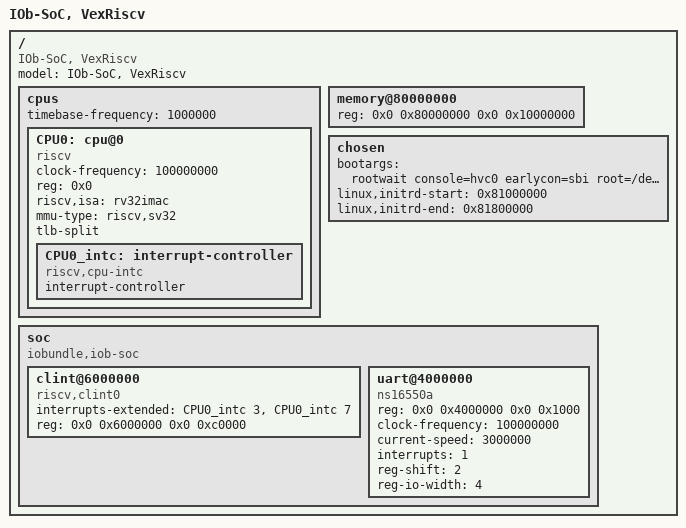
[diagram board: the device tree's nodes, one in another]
/dts-v1/;

/ {
  #address-cells = <2>;
  #size-cells = <2>;
  model = "IOb-SoC, VexRiscv";
  compatible = "IOb-SoC, VexRiscv";
	cpus {
    #address-cells = <0x1>;
    #size-cells = <0x0>;
    timebase-frequency = <1000000>;
		CPU0: cpu@0 {
			clock-frequency = <100000000>;
      device_type = "cpu";
			reg = <0x0>;
			status = "okay";
      compatible = "riscv";
			riscv,isa = "rv32imac";
			mmu-type = "riscv,sv32";
			tlb-split;
			CPU0_intc: interrupt-controller {
				#interrupt-cells = <1>;
				interrupt-controller;
				compatible = "riscv,cpu-intc";
			};
		};
	};
	memory@80000000 {
    device_type = "memory";
    reg = <0x0 0x80000000 0x0 0x10000000>;
	};
  chosen {
  	bootargs = "rootwait console=hvc0 earlycon=sbi root=/dev/ram0 init=/sbin/init";
  	linux,initrd-start = <0x81000000>;
  	linux,initrd-end = <0x81800000>; // max 8MB ramdisk image
  };
  soc {
    #address-cells = <2>;
    #size-cells = <2>;
    compatible = "iobundle,iob-soc", "simple-bus";
    ranges;
    clint@6000000 {
      compatible = "riscv,clint0";
      interrupts-extended = <&CPU0_intc 3 &CPU0_intc 7>;
      reg = <0x0 0x6000000 0x0 0xc0000>;
      reg-names = "control";
    };
    uart@4000000 {
      compatible = "ns16550a";
      reg = <0x0 0x4000000 0x0 0x1000>;
      clock-frequency = <100000000>;
      current-speed = <3000000>;
      // interrupt-parent = <&PLIC0>;
      interrupts = <1>;
      reg-shift = <2>; // regs are spaced on 32 bit boundary
      reg-io-width = <4>; // only 32-bit access are supported
    };
  };
};
